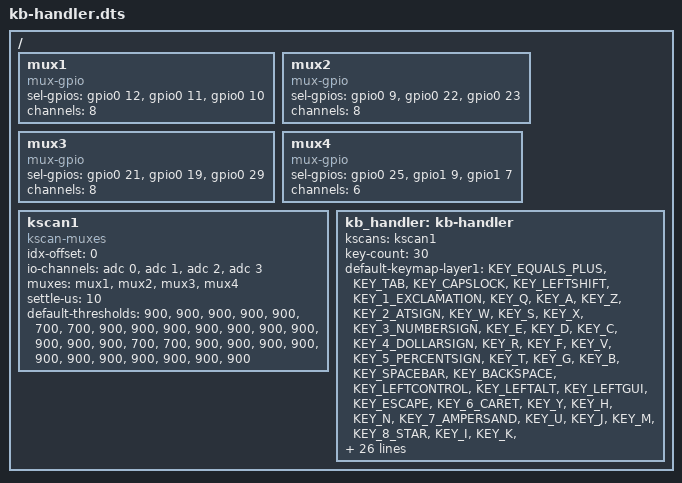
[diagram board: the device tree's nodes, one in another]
#include <zephyr/dt-bindings/input/input-event-codes.h>

#include <dt-bindings/kb-handler/kb-key-codes.h>

/ {

	mux1: mux1 {
		compatible = "mux-gpio";
		sel-gpios = <&gpio0 12 GPIO_ACTIVE_HIGH>,
			<&gpio0 11 GPIO_ACTIVE_HIGH>, <&gpio0 10 GPIO_ACTIVE_HIGH>;
		channels = <8>;
		#mux-cells = <0>;
	};
	mux2: mux2 {
		compatible = "mux-gpio";
		sel-gpios = <&gpio0 9 GPIO_ACTIVE_HIGH>,
			<&gpio0 22 GPIO_ACTIVE_HIGH>, <&gpio0 23 GPIO_ACTIVE_HIGH>;
		channels = <8>;
		#mux-cells = <0>;
	};
	mux3: mux3 {
		compatible = "mux-gpio";
		sel-gpios = <&gpio0 21 GPIO_ACTIVE_HIGH>,
			<&gpio0 19 GPIO_ACTIVE_HIGH>, <&gpio0 29 GPIO_ACTIVE_HIGH>;
		channels = <8>;
		#mux-cells = <0>;
	};
	mux4: mux4 {
		compatible = "mux-gpio";
		sel-gpios = <&gpio0 25 GPIO_ACTIVE_HIGH>,
			<&gpio1 9 GPIO_ACTIVE_HIGH>, <&gpio1 7 GPIO_ACTIVE_HIGH>;
		channels = <6>;
		#mux-cells = <0>;
	};

	kscan1: kscan1 {

		compatible = "kscan-muxes";

		// handles indexes [0-7], [8-15], [16-23], [24-29]
		idx-offset = <0>;
		io-channels = <&adc 0>, <&adc 1>, <&adc 2>, <&adc 3>; // P0.04, P0.05, P0.06, P0.07
		muxes = <&mux1>, <&mux2>, <&mux3>, <&mux4>;

		settle-us = <10>;
		default-thresholds = <900>, <900>, <900>, <900>, <900>, <700>,
			<700>, <900>, <900>, <900>, <900>, <900>, <900>, <900>, <900>,
			<900>, <900>, <700>, <700>, <900>, <900>, <900>, <900>, <900>,
			<900>, <900>, <900>, <900>, <900>, <900>;

		#kscan-cells = <0>;
	};

	kb_handler: kb-handler {

		kscans = <&kscan1>;

		key-count = <30>;

		default-keymap-layer1 =
			// Left (30)
			<KEY_EQUALS_PLUS>, <KEY_TAB>, <KEY_CAPSLOCK>, <KEY_LEFTSHIFT>,
			<KEY_1_EXCLAMATION>, <KEY_Q>, <KEY_A>, <KEY_Z>, <KEY_2_ATSIGN>,
			<KEY_W>, <KEY_S>, <KEY_X>, <KEY_3_NUMBERSIGN>, <KEY_E>, <KEY_D>,
			<KEY_C>, <KEY_4_DOLLARSIGN>, <KEY_R>, <KEY_F>, <KEY_V>,
			<KEY_5_PERCENTSIGN>, <KEY_T>, <KEY_G>, <KEY_B>, <KEY_SPACEBAR>,
			<KEY_BACKSPACE>, <KEY_LEFTCONTROL>, <KEY_LEFTALT>, <KEY_LEFTGUI>,
			<KEY_ESCAPE>,

			// Right (30)
			<KEY_6_CARET>, <KEY_Y>, <KEY_H>, <KEY_N>, <KEY_7_AMPERSAND>,
			<KEY_U>, <KEY_J>, <KEY_M>, <KEY_8_STAR>, <KEY_I>, <KEY_K>,
			<KEY_COMMA_LESSTHAN>, <KEY_9_LPAREN>, <KEY_O>, <KEY_L>,
			<KEY_DOT_GREATERTHAN>, <KEY_0_RPAREN>, <KEY_P>,
			<KEY_SEMICOLON_COLON>, <KEY_SLASH_QUESTIONMARK>,
			<KEY_MINUS_UNDERSCORE>, <KEY_BACKSLASH_VERTICALBAR>,
			<KEY_APOSTROPHE_QUOTES>, <KEY_RIGHTSHIFT>, <KEY_LAYER1>,
			<KEY_ENTER>, <KEY_RIGHTCONTROL>, <KEY_RIGHTALT>, <KEY_RIGHTGUI>,
			<KEY_FN>;

		default-keymap-layer2 =
			// Left (30)
			<KEY_F12>, <KEY_NOKEY>, <KEY_NOKEY>, <KEY_NOKEY>, <KEY_F1>,
			<KEY_NOKEY>, <KEY_NOKEY>, <KEY_NOKEY>, <KEY_F2>, <KEY_NOKEY>,
			<KEY_NOKEY>, <KEY_NOKEY>, <KEY_F3>, <KEY_NOKEY>, <KEY_NOKEY>,
			<KEY_NOKEY>, <KEY_F4>, <KEY_NOKEY>, <KEY_NOKEY>, <KEY_NOKEY>,
			<KEY_F5>, <KEY_NOKEY>, <KEY_NOKEY>, <KEY_NOKEY>, <KEY_NOKEY>,
			<KEY_NOKEY>, <KEY_NOKEY>, <KEY_NOKEY>, <KEY_NOKEY>, <KEY_NOKEY>,

			// Right (30)
			<KEY_F6>, <KEY_NOKEY>, <KEY_LEFTARROW>, <KEY_NOKEY>, <KEY_F7>,
			<KEY_NOKEY>, <KEY_DOWNARROW>, <KEY_NOKEY>, <KEY_F8>, <KEY_NOKEY>,
			<KEY_UPARROW>, <KEY_NOKEY>, <KEY_F9>, <KEY_SQBRACKETL_CURBRACEL>,
			<KEY_RIGHTARROW>, <KEY_NOKEY>, <KEY_F10>,
			<KEY_SQBRACKETR_CURBRACER>, <KEY_NOKEY>, <KEY_NOKEY>, <KEY_F11>,
			<KEY_NOKEY>, <KEY_NOKEY>, <KEY_NOKEY>, <KEY_NOKEY>, <KEY_NOKEY>,
			<KEY_NOKEY>, <KEY_NOKEY>, <KEY_NOKEY>, <KEY_NOKEY>;
	};
};
